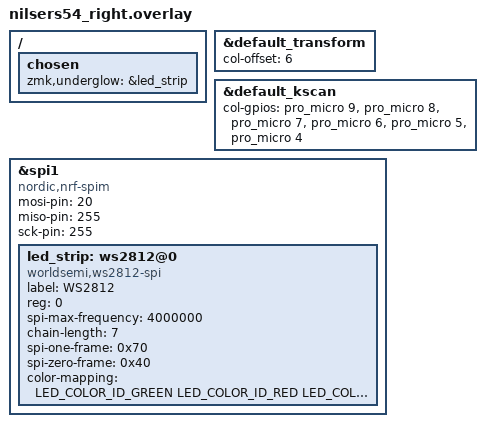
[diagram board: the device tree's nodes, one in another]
#include "nilsers54.dtsi"
#include <dt-bindings/led/led.h>

&default_transform {
    col-offset = <6>;
};

&default_kscan {
    col-gpios
        = <&pro_micro 9 GPIO_ACTIVE_HIGH>
        , <&pro_micro 8 GPIO_ACTIVE_HIGH>
        , <&pro_micro 7 GPIO_ACTIVE_HIGH>
        , <&pro_micro 6 GPIO_ACTIVE_HIGH>
        , <&pro_micro 5 GPIO_ACTIVE_HIGH>
        , <&pro_micro 4 GPIO_ACTIVE_HIGH>
        ;
};

&spi1 {
    compatible = "nordic,nrf-spim";
    status = "okay";
    mosi-pin = <20>;
    miso-pin = <255>;
    sck-pin = <255>;

    led_strip: ws2812@0 {
        compatible = "worldsemi,ws2812-spi";
        label = "WS2812";
        reg = <0>;
        spi-max-frequency = <4000000>;
        chain-length = <7>;
        spi-one-frame = <0x70>;
        spi-zero-frame = <0x40>;
        color-mapping = <LED_COLOR_ID_GREEN
                         LED_COLOR_ID_RED
                         LED_COLOR_ID_BLUE>;
    };
};

/ {
    chosen {
        zmk,underglow = &led_strip;
    };
};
